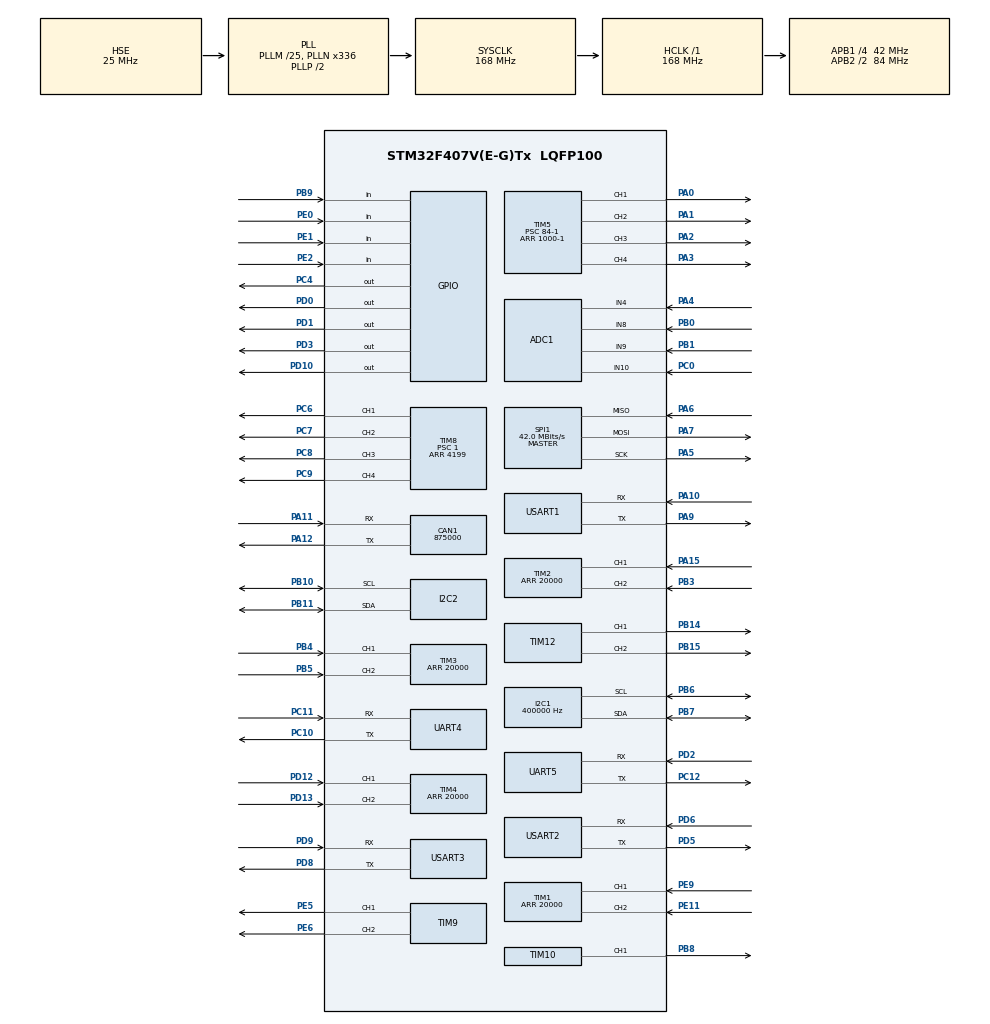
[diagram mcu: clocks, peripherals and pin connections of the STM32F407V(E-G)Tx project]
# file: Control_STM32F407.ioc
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ADC1.Channel-0\#ChannelRegularConversion=ADC_CHANNEL_4
ADC1.NbrOfConversionFlag=1
ADC1.Rank-0\#ChannelRegularConversion=1
ADC1.SamplingTime-0\#ChannelRegularConversion=ADC_SAMPLETIME_3CYCLES
ADC1.master=1
CAN1.CalculateBaudRate=875000
CAN1.CalculateTimeBit=1142
CAN1.CalculateTimeQuantum=380.95238095238096
Dma.Request0=USART3_RX
Dma.USART3_RX.0.Direction=DMA_PERIPH_TO_MEMORY
Dma.USART3_RX.0.FIFOMode=DMA_FIFOMODE_ENABLE
Dma.USART3_RX.0.FIFOThreshold=DMA_FIFO_THRESHOLD_FULL
Dma.USART3_RX.0.Instance=DMA1_Stream1
Dma.USART3_RX.0.MemBurst=DMA_MBURST_SINGLE
Dma.USART3_RX.0.MemDataAlignment=DMA_MDATAALIGN_BYTE
Dma.USART3_RX.0.MemInc=DMA_MINC_ENABLE
Dma.USART3_RX.0.Mode=DMA_NORMAL
Dma.USART3_RX.0.PeriphBurst=DMA_PBURST_SINGLE
Dma.USART3_RX.0.PeriphDataAlignment=DMA_PDATAALIGN_BYTE
Dma.USART3_RX.0.PeriphInc=DMA_PINC_DISABLE
Dma.USART3_RX.0.Priority=DMA_PRIORITY_LOW
I2C1.ClockSpeed=400000
I2C1.I2C_Mode=I2C_Fast
I2C2.I2C_Mode=I2C_Fast
Mcu.Family=STM32F4
Mcu.Name=STM32F407V(E-G)Tx
Mcu.Package=LQFP100
NVIC.DMA1_Stream1_IRQn=true\:0\:0\:false\:false\:true\:false\:true\:true
NVIC.PriorityGroup=NVIC_PRIORITYGROUP_4
NVIC.TIM1_BRK_TIM9_IRQn=true\:1\:0\:true\:false\:true\:true\:true\:true
NVIC.TIM1_CC_IRQn=true\:1\:0\:true\:false\:true\:true\:true\:true
NVIC.TIM1_TRG_COM_TIM11_IRQn=true\:1\:0\:true\:false\:true\:true\:true\:true
NVIC.TIM1_UP_TIM10_IRQn=true\:1\:0\:true\:false\:true\:true\:true\:true
NVIC.TIM2_IRQn=true\:1\:0\:true\:false\:true\:true\:true\:true
NVIC.TIM3_IRQn=true\:1\:0\:true\:false\:true\:true\:true\:true
NVIC.TIM4_IRQn=true\:1\:0\:true\:false\:true\:true\:true\:true
NVIC.TIM8_UP_TIM13_IRQn=true\:2\:0\:true\:false\:true\:true\:true\:true
NVIC.USART3_IRQn=true\:0\:0\:false\:false\:true\:true\:true\:true
PA0-WKUP.Signal=S_TIM5_CH1
PA1.Signal=S_TIM5_CH2
PA10.Mode=Asynchronous
PA10.Signal=USART1_RX
PA11.Mode=CAN_Activate
PA11.Signal=CAN1_RX
PA12.Mode=CAN_Activate
PA12.Signal=CAN1_TX
PA13.Mode=Serial_Wire
PA13.Signal=SYS_JTMS-SWDIO
PA14.Mode=Serial_Wire
PA14.Signal=SYS_JTCK-SWCLK
PA15.GPIO_PuPd=GPIO_PULLUP
PA15.Signal=S_TIM2_CH1_ETR
PA2.Signal=S_TIM5_CH3
PA3.Signal=S_TIM5_CH4
PA4.Signal=ADCx_IN4
PA5.Mode=Full_Duplex_Master
PA5.Signal=SPI1_SCK
PA6.Mode=Full_Duplex_Master
PA6.Signal=SPI1_MISO
PA7.Mode=Full_Duplex_Master
PA7.Signal=SPI1_MOSI
PA9.Mode=Asynchronous
PA9.Signal=USART1_TX
PB0.Signal=ADCx_IN8
PB1.Signal=ADCx_IN9
PB10.Mode=I2C
PB10.Signal=I2C2_SCL
PB11.Mode=I2C
PB11.Signal=I2C2_SDA
PB14.Signal=S_TIM12_CH1
PB15.Signal=S_TIM12_CH2
PB3.GPIO_PuPd=GPIO_PULLUP
PB3.Signal=S_TIM2_CH2
PB4.GPIO_PuPd=GPIO_PULLUP
PB4.Signal=S_TIM3_CH1
PB5.GPIO_PuPd=GPIO_PULLUP
PB5.Signal=S_TIM3_CH2
PB6.Mode=I2C
PB6.Signal=I2C1_SCL
PB7.Mode=I2C
PB7.Signal=I2C1_SDA
PB8.Signal=S_TIM10_CH1
PB9.GPIO_PuPd=GPIO_PULLUP
PB9.Signal=GPIO_Input
PC0.Signal=ADCx_IN10
PC10.Mode=Asynchronous
PC10.Signal=UART4_TX
PC11.Mode=Asynchronous
PC11.Signal=UART4_RX
PC12.Mode=Asynchronous
PC12.Signal=UART5_TX
PC4.Signal=GPIO_Output
PC6.Signal=S_TIM8_CH1
PC7.Signal=S_TIM8_CH2
PC8.Signal=S_TIM8_CH3
PC9.Signal=S_TIM8_CH4
PD0.Signal=GPIO_Output
PD1.Signal=GPIO_Output
PD10.Signal=GPIO_Output
PD12.GPIO_PuPd=GPIO_PULLUP
PD12.Signal=S_TIM4_CH1
PD13.GPIO_PuPd=GPIO_PULLUP
PD13.Signal=S_TIM4_CH2
PD2.Mode=Asynchronous
PD2.Signal=UART5_RX
PD3.Signal=GPIO_Output
PD5.Mode=Asynchronous
PD5.Signal=USART2_TX
PD6.Mode=Asynchronous
PD6.Signal=USART2_RX
PD8.Mode=Asynchronous
PD8.Signal=USART3_TX
PD9.Mode=Asynchronous
PD9.Signal=USART3_RX
PE0.GPIO_PuPd=GPIO_PULLUP
PE0.Signal=GPIO_Input
PE1.GPIO_PuPd=GPIO_PULLUP
PE1.Signal=GPIO_Input
PE11.GPIO_PuPd=GPIO_PULLUP
PE11.Signal=S_TIM1_CH2
PE2.GPIO_PuPd=GPIO_PULLUP
PE2.Signal=GPIO_Input
PE5.Signal=S_TIM9_CH1
PE6.Signal=S_TIM9_CH2
PE9.GPIO_PuPd=GPIO_PULLUP
PE9.Signal=S_TIM1_CH1
PH0-OSC_IN.Mode=HSE-External-Oscillator
PH0-OSC_IN.Signal=RCC_OSC_IN
PH1-OSC_OUT.Mode=HSE-External-Oscillator
PH1-OSC_OUT.Signal=RCC_OSC_OUT
ProjectManager.HeapSize=0x200
ProjectManager.StackSize=0x400
ProjectManager.TargetToolchain=MDK-ARM V5.32
RCC.48MHZClocksFreq_Value=84000000
RCC.AHBFreq_Value=168000000
RCC.APB1CLKDivider=RCC_HCLK_DIV4
RCC.APB1Freq_Value=42000000
RCC.APB1TimFreq_Value=84000000
RCC.APB2CLKDivider=RCC_HCLK_DIV2
RCC.APB2Freq_Value=84000000
RCC.APB2TimFreq_Value=168000000
RCC.CortexFreq_Value=168000000
RCC.HCLKFreq_Value=168000000
RCC.HSE_VALUE=25000000
RCC.HSI_VALUE=16000000
RCC.LSE_VALUE=32768
RCC.PLLM=25
RCC.PLLN=336
RCC.PLLSourceVirtual=RCC_PLLSOURCE_HSE
RCC.SYSCLKFreq_VALUE=168000000
RCC.SYSCLKSource=RCC_SYSCLKSOURCE_PLLCLK
RCC.VCOOutputFreq_Value=336000000
SH.ADCx_IN10.0=ADC1_IN10,IN10
SH.ADCx_IN4.0=ADC1_IN4,IN4
SH.ADCx_IN8.0=ADC1_IN8,IN8
SH.ADCx_IN9.0=ADC1_IN9,IN9
SH.S_TIM10_CH1.0=TIM10_CH1,PWM Generation1 CH1
SH.S_TIM12_CH1.0=TIM12_CH1,PWM Generation1 CH1
SH.S_TIM12_CH2.0=TIM12_CH2,PWM Generation2 CH2
SH.S_TIM1_CH1.0=TIM1_CH1,Encoder_Interface
SH.S_TIM1_CH2.0=TIM1_CH2,Encoder_Interface
SH.S_TIM2_CH1_ETR.0=TIM2_CH1,Encoder_Interface
SH.S_TIM2_CH2.0=TIM2_CH2,Encoder_Interface
SH.S_TIM3_CH1.0=TIM3_CH1,Encoder_Interface
SH.S_TIM3_CH2.0=TIM3_CH2,Encoder_Interface
SH.S_TIM4_CH1.0=TIM4_CH1,Encoder_Interface
SH.S_TIM4_CH2.0=TIM4_CH2,Encoder_Interface
SH.S_TIM5_CH1.0=TIM5_CH1,PWM Generation1 CH1
SH.S_TIM5_CH2.0=TIM5_CH2,PWM Generation2 CH2
SH.S_TIM5_CH3.0=TIM5_CH3,PWM Generation3 CH3
SH.S_TIM5_CH4.0=TIM5_CH4,PWM Generation4 CH4
SH.S_TIM8_CH1.0=TIM8_CH1,PWM Generation1 CH1
SH.S_TIM8_CH2.0=TIM8_CH2,PWM Generation2 CH2
SH.S_TIM8_CH3.0=TIM8_CH3,PWM Generation3 CH3
SH.S_TIM8_CH4.0=TIM8_CH4,PWM Generation4 CH4
SH.S_TIM9_CH1.0=TIM9_CH1,PWM Generation1 CH1
SH.S_TIM9_CH2.0=TIM9_CH2,PWM Generation2 CH2
SPI1.CalculateBaudRate=42.0 MBits/s
SPI1.Direction=SPI_DIRECTION_2LINES
SPI1.Mode=SPI_MODE_MASTER
SPI1.VirtualType=VM_MASTER
STMicroelectronics.X-CUBE-ALGOBUILD.1.4.0.LibraryCcDSPOoLibraryJjDSPOoLibrary=true
TIM1.EncoderMode=TIM_ENCODERMODE_TI12
TIM1.Period=20000
TIM10.Channel=TIM_CHANNEL_1
TIM12.Channel-PWM\ Generation1\ CH1=TIM_CHANNEL_1
TIM12.Channel-PWM\ Generation2\ CH2=TIM_CHANNEL_2
TIM13.AutoReloadPreload=TIM_AUTORELOAD_PRELOAD_ENABLE
TIM13.Period=1000-1
TIM13.Prescaler=84-1
TIM2.EncoderMode=TIM_ENCODERMODE_TI12
TIM2.Period=20000
TIM3.EncoderMode=TIM_ENCODERMODE_TI12
TIM3.Period=20000
TIM4.EncoderMode=TIM_ENCODERMODE_TI12
TIM4.Period=20000
TIM5.AutoReloadPreload=TIM_AUTORELOAD_PRELOAD_ENABLE
TIM5.Channel-PWM\ Generation1\ CH1=TIM_CHANNEL_1
TIM5.Channel-PWM\ Generation2\ CH2=TIM_CHANNEL_2
TIM5.Channel-PWM\ Generation3\ CH3=TIM_CHANNEL_3
TIM5.Channel-PWM\ Generation4\ CH4=TIM_CHANNEL_4
TIM5.Period=1000-1
TIM5.Prescaler=84-1
TIM8.AutoReloadPreload=TIM_AUTORELOAD_PRELOAD_ENABLE
TIM8.Channel-PWM\ Generation1\ CH1=TIM_CHANNEL_1
TIM8.Channel-PWM\ Generation2\ CH2=TIM_CHANNEL_2
TIM8.Channel-PWM\ Generation3\ CH3=TIM_CHANNEL_3
TIM8.Channel-PWM\ Generation4\ CH4=TIM_CHANNEL_4
TIM8.Period=4199
TIM8.Prescaler=1
TIM9.Channel-PWM\ Generation1\ CH1=TIM_CHANNEL_1
TIM9.Channel-PWM\ Generation2\ CH2=TIM_CHANNEL_2
UART4.VirtualMode=Asynchronous
UART5.VirtualMode=Asynchronous
USART1.VirtualMode=VM_ASYNC
USART2.VirtualMode=VM_ASYNC
USART3.VirtualMode=VM_ASYNC
VP_STMicroelectronics.X-CUBE-ALGOBUILD_VS_DSPOoLibraryJjLibrary_1.4.0_1.4.0.Mode=DSPOoLibraryJjLibrary
VP_TIM10_VS_ClockSourceINT.Mode=Enable_Timer
VP_TIM12_VS_ClockSourceINT.Mode=Internal
VP_TIM13_VS_ClockSourceINT.Mode=Enable_Timer
VP_TIM5_VS_ClockSourceINT.Mode=Internal
VP_TIM8_VS_ClockSourceINT.Mode=Internal
VP_TIM9_VS_ClockSourceINT.Mode=Internal
board=custom

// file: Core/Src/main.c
/* USER CODE BEGIN Header */
/**
  ******************************************************************************
  * @file           : main.c
  * @brief          : Main program body
  ******************************************************************************
  * @attention
  *
  * Copyright (c) 2025 STMicroelectronics.
  * All rights reserved.
  *
  * This software is licensed under terms that can be found in the LICENSE file
  * in the root directory of this software component.
  * If no LICENSE file comes with this software, it is provided AS-IS.
  *
  ******************************************************************************
  */
/* USER CODE END Header */
#include "main.h"
#include "adc.h"
#include "can.h"
#include "dma.h"
#include "i2c.h"
#include "spi.h"
#include "tim.h"
#include "usart.h"
#include "gpio.h"

/* USER CODE BEGIN Includes */
#include "headfile.h"

/* USER CODE END Includes */

void SystemClock_Config(void);

int main(void)
{

  /* MCU Configuration--------------------------------------------------------*/

  /* Reset of all peripherals, Initializes the Flash interface and the Systick. */
  HAL_Init();

  /* Configure the system clock */
  SystemClock_Config();

  /* Initialize all configured peripherals */
  MX_GPIO_Init();
  MX_DMA_Init();
  MX_ADC1_Init();
  MX_CAN1_Init();
  MX_I2C1_Init();
  MX_I2C2_Init();
  MX_SPI1_Init();
  MX_TIM1_Init();
  MX_TIM2_Init();
  MX_TIM3_Init();
  MX_TIM4_Init();
  MX_TIM5_Init();
  MX_TIM9_Init();
  MX_TIM12_Init();
  MX_UART5_Init();
  MX_USART1_UART_Init();
  MX_USART2_UART_Init();
  MX_USART3_UART_Init();
  MX_TIM8_Init();
  MX_UART4_Init();
  MX_TIM10_Init();
  MX_TIM13_Init();
  /* USER CODE BEGIN 2 */
	Task_Run();
  /* USER CODE END 2 */

  /* Infinite loop */
  while (1)
  {

  }
}

void SystemClock_Config(void)
{
  RCC_OscInitTypeDef RCC_OscInitStruct = {0};
  RCC_ClkInitTypeDef RCC_ClkInitStruct = {0};

  /** Configure the main internal regulator output voltage
  */
  __HAL_RCC_PWR_CLK_ENABLE();
  __HAL_PWR_VOLTAGESCALING_CONFIG(PWR_REGULATOR_VOLTAGE_SCALE1);

  /** Initializes the RCC Oscillators according to the specified parameters
  * in the RCC_OscInitTypeDef structure.
  */
  RCC_OscInitStruct.OscillatorType = RCC_OSCILLATORTYPE_HSE;
  RCC_OscInitStruct.HSEState = RCC_HSE_ON;
  RCC_OscInitStruct.PLL.PLLState = RCC_PLL_ON;
  RCC_OscInitStruct.PLL.PLLSource = RCC_PLLSOURCE_HSE;
  RCC_OscInitStruct.PLL.PLLM = 25;
  RCC_OscInitStruct.PLL.PLLN = 336;
  RCC_OscInitStruct.PLL.PLLP = RCC_PLLP_DIV2;
  RCC_OscInitStruct.PLL.PLLQ = 4;
  if (HAL_RCC_OscConfig(&RCC_OscInitStruct) != HAL_OK)
  {
    Error_Handler();
  }

  /** Initializes the CPU, AHB and APB buses clocks
  */
  RCC_ClkInitStruct.ClockType = RCC_CLOCKTYPE_HCLK|RCC_CLOCKTYPE_SYSCLK
                              |RCC_CLOCKTYPE_PCLK1|RCC_CLOCKTYPE_PCLK2;
  RCC_ClkInitStruct.SYSCLKSource = RCC_SYSCLKSOURCE_PLLCLK;
  RCC_ClkInitStruct.AHBCLKDivider = RCC_SYSCLK_DIV1;
  RCC_ClkInitStruct.APB1CLKDivider = RCC_HCLK_DIV4;
  RCC_ClkInitStruct.APB2CLKDivider = RCC_HCLK_DIV2;

  if (HAL_RCC_ClockConfig(&RCC_ClkInitStruct, FLASH_LATENCY_5) != HAL_OK)
  {
    Error_Handler();
  }
}

void Error_Handler(void)
{
  __disable_irq();
  while (1)
  {
  }
}
